# S32K324_M7 register map
Vendor: NXP Semiconductors; File version: 1.1
CPU: CM7 r0p1, little endian, MPU, FPU, VTOR, 4 interrupt priority bits
Registers are 32-bit, read-write, reset 0x0 unless marked. A register's access mark holds for its fields unless they carry their own. Offsets are from the block's base; [hi:lo] are bit positions; {n}, {i} and the like mark numbered series; 'fields as' and 'values as' point back to an identical list.

## EMAC (part 3 of 3)
Base 0x40480000
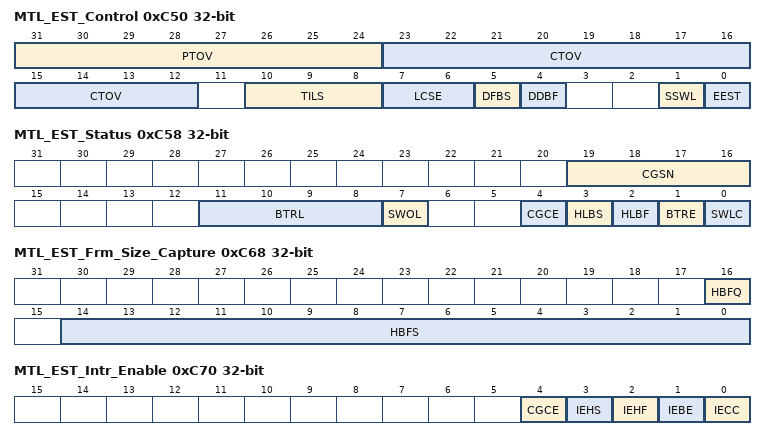
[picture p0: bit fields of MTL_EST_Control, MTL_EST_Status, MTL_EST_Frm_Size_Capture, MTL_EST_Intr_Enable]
0xC50 MTL_EST_Control
  [31:24] PTOV — PTP Time Offset Value
  [23:12] CTOV — Current Time Offset Value
  [10:8] TILS — Time Interval Left Shift Amount
  [7:6] LCSE — Loop Count to Report Scheduling Error
    0=M_4_ITERNS (4 iterations); 1=M_8_ITERNS (8 iterations); 2=M_16_ITERNS (16 iterations); 3=M_32_ITERNS (32 iterations)
  [5] DFBS — Drop Frames Causing Scheduling Error
    0=DONT_DROP (Do not drop frames); 1=DROP (Drop frames)
  [4] DDBF — Do not Drop Frames during Frame Size Error
    0=DROP (Drop frames during frame size error); 1=DONT_DROP (Do not Drop frames during frame size error)
  [1] SSWL — Switch to Software Owned List
    0=DISABLE (Disabled); 1=ENABLE (Enabled)
  [0] EEST — Enable EST
    0=DISABLE (Disabled); 1=ENABLE (Enabled)
0xC58 MTL_EST_Status
  [19:16] CGSN ro — Current GCL Slot Number Indicates the slot number of the GCL list
  [11:8] BTRL ro — BTR Error Loop Count Provides the minimum count (N) for which the equation Current Time =< New BTR + (N * New Cycle Time) becomes true
  [7] SWOL ro — S/W owned list When '0' indicates Gate control list number "0" is owned by software and when "1" indicates the Gate Control list "1" is owned by the software
    0=INACTIVE (Gate control list number "0" is owned by software); 1=ACTIVE (Gate control list number "1" is owned by software)
  [4] CGCE — Constant Gate Control Error This error occurs when the list length (LLR) is 1 and the Cycle Time (CTR) is less than or equal to the programmed Time Interval (TI) value after the optional Left Shifting
    0=INACTIVE (Constant Gate Control Error not detected); 1=ACTIVE (Constant Gate Control Error detected)
  [3] HLBS ro — Head-Of-Line Blocking due to Scheduling Set when the frame is not able to win arbitration and get scheduled even after 4 iterations of the GCL
    0=INACTIVE (Head-Of-Line Blocking due to Scheduling not detected); 1=ACTIVE (Head-Of-Line Blocking due to Scheduling detected)
  [2] HLBF ro — Head-Of-Line Blocking due to Frame Size Set when HOL Blocking is noticed on one or more Queues as a result of none of the Time Intervals of gate open in the GCL being greater than or equal to the duration needed for frame size (or frame fragment size when preemption is enabled) transmission
    0=INACTIVE (Head-Of-Line Blocking due to Frame Size not detected); 1=ACTIVE (Head-Of-Line Blocking due to Frame Size detected)
  [1] BTRE — BTR Error
    0=INACTIVE (BTR Error not detected); 1=ACTIVE (BTR Error detected)
  [0] SWLC — Switch to Software Owned List Complete
    0=INACTIVE (Not detected); 1=ACTIVE (Detected)
0xC60 MTL_EST_Sch_Error — MTL EST Scheduling Error
  [1:0] SEQN — Schedule Error Queue Number
0xC64 MTL_EST_Frm_Size_Error — MTL EST Frame Size Error
  [1:0] FEQN — Frame Size Error Queue Number
0xC68 MTL_EST_Frm_Size_Capture ro — MTL EST Frame Size Capture
  [16] HBFQ — Queue Number of HLBF
  [14:0] HBFS — Frame Size of HLBF
0xC70 MTL_EST_Intr_Enable — MTL EST Interrupt Enable
  [all] fields
    0=DISABLE (Disabled); 1=ENABLE (Enabled)
  [4] CGCE — Interrupt Enable for CGCE
  [3] IEHS — Interrupt Enable for HLBS
  [2] IEHF — Interrupt Enable for HLBF
  [1] IEBE — Interrupt Enable for BTR Error
  [0] IECC — Interrupt Enable for Switch List
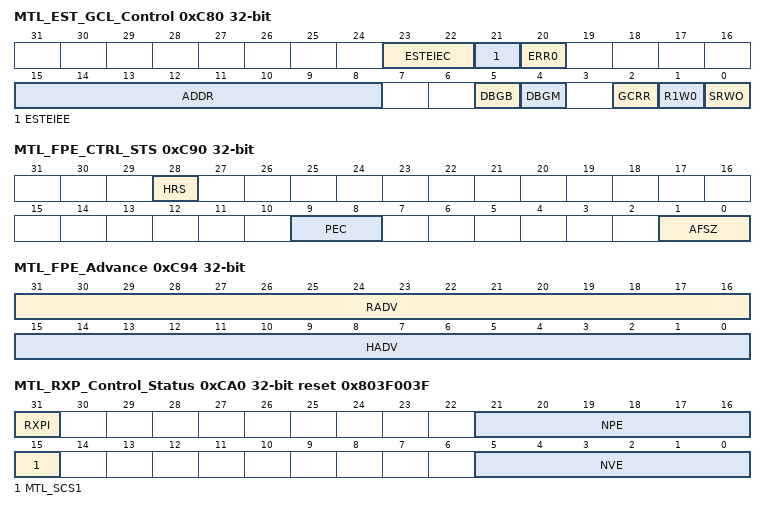
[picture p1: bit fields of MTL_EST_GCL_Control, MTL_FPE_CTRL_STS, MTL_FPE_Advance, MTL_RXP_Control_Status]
0xC80 MTL_EST_GCL_Control
  [23:22] ESTEIEC — ECC Inject Error Control for EST Memory
    0=M_1BIT (Insert 1 bit error); 1=M_2BIT (Insert 2 bit errors); 2=M_3BIT (Insert 3 bit errors); 3=M_1BIT_ADDR (Insert 1 bit error in address field)
  [21] ESTEIEE — EST ECC Inject Error Enable
    0=DISABLE (Disabled); 1=ENABLE (Enabled)
  [20] ERR0 — If this field is 1, it indicates that when the software writes to GCL the last write operation was aborted and when MTL_EST_Control[SSWL] is 1, GCL registers are prohibited
    0=DISABLE (ERR0 is disabled); 1=ENABLE (ERR1 is enabled)
  [15:8] ADDR — Gate Control List Address: (GCLA when GCRR is "0")
  [5] DBGB — Debug Mode Bank Select
    0=BANK0 (Directed to bank 0); 1=BANK1 (Directed to bank 1)
  [4] DBGM — Debug Mode
    0=DISABLE (Disabled); 1=ENABLE (Enabled)
  [2] GCRR — Gate Control Related Registers
    0=DISABLE (Disabled); 1=ENABLE (Enabled)
  [1] R1W0 — Read '1', Write '0'
    0=WRITE (Write operation); 1=READ (Read operation)
  [0] SRWO — Start Read/Write Operation
    0=DISABLE (Disabled); 1=ENABLE (Enabled)
0xC84 MTL_EST_GCL_Data
  [31:0] GCD — Gate Control Data
0xC90 MTL_FPE_CTRL_STS — MTL FPE Control Status
  [28] HRS ro — Hold/Release Status
    0=SET_REL (Release state); 1=SET_HOLD (Hold state)
  [9:8] PEC — Preemption Classification
  [1:0] AFSZ — Additional Fragment Size
0xC94 MTL_FPE_Advance
  [31:16] RADV — Release Advance
  [15:0] HADV — Hold Advance
0xCA0 MTL_RXP_Control_Status reset 0x803F003F — MTL Rx Parser Control Status
  [31] RXPI ro — RX Parser in Idle State
    0=INACTIVE (Not in Idle state); 1=ACTIVE (Idle state)
  [21:16] NPE — Number of parsable entries in the Instruction table
  [15] MTL_SCS1
  [5:0] NVE — Number Of Valid Entry Address Or Index In The Instruction Table
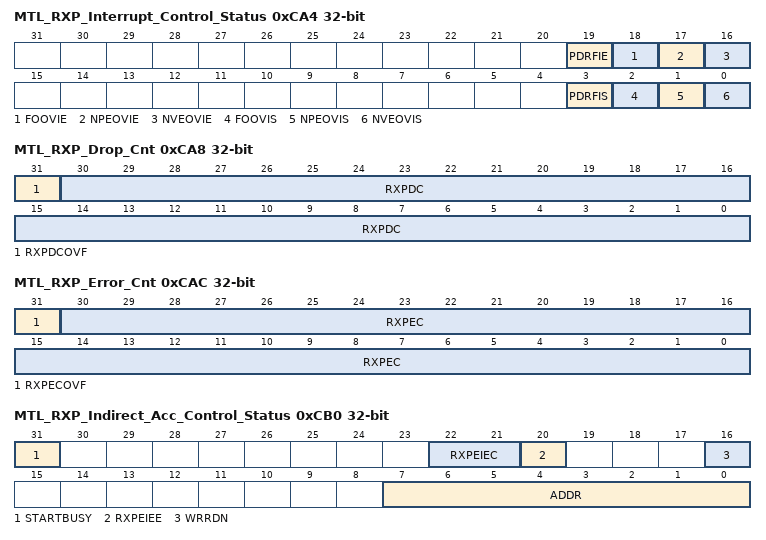
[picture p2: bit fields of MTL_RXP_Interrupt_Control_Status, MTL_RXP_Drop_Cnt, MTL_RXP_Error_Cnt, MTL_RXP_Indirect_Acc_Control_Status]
0xCA4 MTL_RXP_Interrupt_Control_Status — MTL Rx Parser Interrupt Control Status
  [19] PDRFIE — Packet Drop due to RF Interrupt Enable
    0=DISABLE (Disabled); 1=ENABLE (Enabled)
  [18] FOOVIE — Frame Offset Overflow Interrupt Enable
    0=DISABLE (Disabled); 1=ENABLE (Enabled)
  [17] NPEOVIE — Number of Parsable Entries Overflow Interrupt Enable
    0=DISABLE; 1=ENABLE
  [16] NVEOVIE — Number of Valid Entries Overflow Interrupt Enable
    0=DISABLE; 1=ENABLE
  [3] PDRFIS — Packet Dropped due to RF Interrupt Status
    0=INACTIVE (Not detected); 1=ACTIVE (Detected)
  [2] FOOVIS — Frame Offset Overflow Interrupt Status
    0=INACTIVE (Not detected); 1=ACTIVE (Detected)
  [1] NPEOVIS — Number of Parsable Entries Overflow Interrupt Status
    0=INACTIVE (Not detected); 1=ACTIVE (Detected)
  [0] NVEOVIS — Number of Valid Entry Address/Index Overflow Interrupt Status
    0=INACTIVE (Not detected); 1=ACTIVE (Detected)
0xCA8 MTL_RXP_Drop_Cnt ro — MTL Rx Parser Drop Count
  [31] RXPDCOVF — Rx Parser Drop Counter Overflow Bit
    0=INACTIVE (Not occurred); 1=ACTIVE (Occurred)
  [30:0] RXPDC — Rx Parser Drop Count
0xCAC MTL_RXP_Error_Cnt ro — MTL Rx Parser Error Count
  [31] RXPECOVF — Rx Parser Error Counter Overflow Bit
    0=INACTIVE (Not occurred); 1=ACTIVE (Occurred)
  [30:0] RXPEC — Rx Parser Error Count
0xCB0 MTL_RXP_Indirect_Acc_Control_Status — MTL Rx Parser Indirect Access Control Status
  [31] STARTBUSY — FRP Instruction Table Access Busy
    0=INACTIVE (hardware not busy); 1=ACTIVE (hardware is busy (Read/Write operation from/to the Rx Parser Memory))
  [22:21] RXPEIEC — ECC Inject Error Control for Rx Parser Memory
    values as MTL_EST_GCL_Control.ESTEIEC
  [20] RXPEIEE — ECC Inject Error Enable for Rx Parser Memory
    0=DISABLE (Disabled); 1=ENABLE (Enabled)
  [16] WRRDN — Read Write Control
    0=READ (Read operation to the receive parser memory); 1=WRITE (Write operation to the receive parser memory)
  [7:0] ADDR — FRP Instruction Table Offset Address
0xCB4 MTL_RXP_Indirect_Acc_Data ro — MTL Rx Parser Indirect Access Data
  [31:0] DATA — FRP Instruction Table Write/Read Data
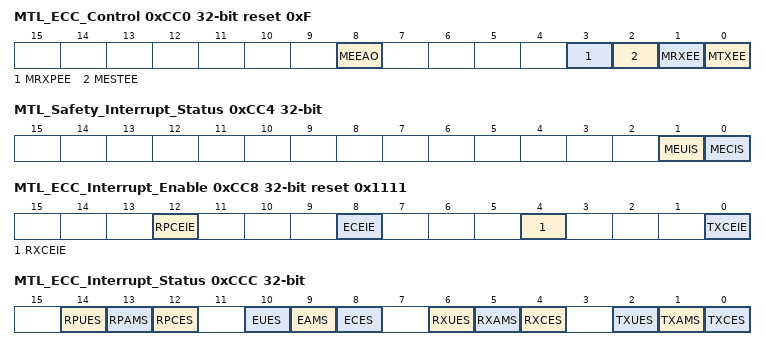
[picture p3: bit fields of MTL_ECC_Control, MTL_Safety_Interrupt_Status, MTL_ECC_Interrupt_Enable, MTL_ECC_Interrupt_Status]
0xCC0 MTL_ECC_Control reset 0xF
  [8] MEEAO — MTL ECC Error Address Status Over-ride
    0=DISABLE; 1=ENABLE
  [3] MRXPEE — MTL Rx Parser ECC Enable
    0=DISABLE (Disabled); 1=ENABLE (Enabled)
  [2] MESTEE — MTL EST ECC Enable
    0=DISABLE (Disabled); 1=ENABLE (Enabled)
  [1] MRXEE — MTL Rx FIFO ECC Enable
    0=DISABLE (Disabled); 1=ENABLE (Enabled)
  [0] MTXEE — MTL Tx FIFO ECC Enable
    0=DISABLE (Disabled); 1=ENABLE (Enabled)
0xCC4 MTL_Safety_Interrupt_Status ro — MTL Safety Interript Status
  [1] MEUIS — MTL ECC Uncorrectable Error Interrupt Status
    0=INACTIVE (Not detected); 1=ACTIVE (Detected)
  [0] MECIS — MTL ECC Correctable Error Interrupt Status
    0=INACTIVE (MTL ECC Correctable error Interrupt Status not detected); 1=ACTIVE (MTL ECC Correctable error Interrupt Status detected)
0xCC8 MTL_ECC_Interrupt_Enable reset 0x1111
  [all] fields
    0=DISABLE (Disabled); 1=ENABLE (Enabled)
  [12] RPCEIE — Rx Parser Memory Correctable Error Interrupt Enable
  [8] ECEIE — EST Memory Correctable Error Interrupt Enable
  [4] RXCEIE — Rx Memory Correctable Error Interrupt Enable
  [0] TXCEIE — Tx Memory Correctable Error Interrupt Enable
0xCCC MTL_ECC_Interrupt_Status
  [all] fields
    0=INACTIVE (Not detected); 1=ACTIVE (Detected)
  [14] RPUES — Rx Parser Memory Uncorrectable Error Status
  [13] RPAMS — MTL Rx Parser Memory Address Mismatch Status
  [12] RPCES — MTL Rx Parser Memory Correctable Error Status
  [10] EUES — MTL EST Memory Uncorrectable Error Status
  [9] EAMS — MTL EST Memory Address Mismatch Status
  [8] ECES — MTL EST Memory Correctable Error Status
  [6] RXUES — MTL Rx Memory Uncorrectable Error Status
  [5] RXAMS — MTL Rx Memory Address Mismatch Status
  [4] RXCES — MTL Rx memory Correctable Error Status
  [2] TXUES — MTL Tx Memory Uncorrectable Error Status
  [1] TXAMS — MTL Tx Memory Address Mismatch Status
  [0] TXCES — MTL Tx Memory Correctable Error Status
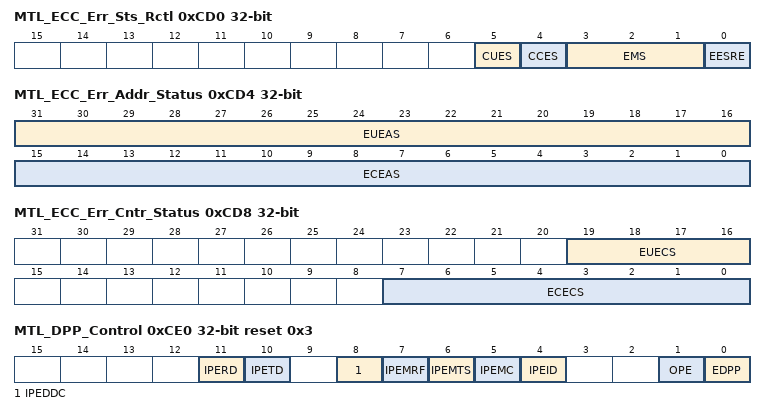
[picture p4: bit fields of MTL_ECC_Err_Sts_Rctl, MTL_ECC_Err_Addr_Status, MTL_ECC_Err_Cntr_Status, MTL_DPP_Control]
0xCD0 MTL_ECC_Err_Sts_Rctl — MTL ECC Error Status
  [5] CUES — Clear Uncorrectable Error Status
    0=INACTIVE (Not detected); 1=ACTIVE (Detected)
  [4] CCES — Clear Correctable Error Status
    0=INACTIVE (Not detected); 1=ACTIVE (Detected)
  [3:1] EMS — MTL ECC Memory Selection
    0=TX_MEM (MTL Tx memory); 1=RX_MEM (MTL Rx memory); 2=EST_MEM (MTL EST memory); 3=RXP_MEM (MTL Rx Parser memory); 4=TSO_MEM (DMA TSO memory)
  [0] EESRE — MTL ECC Error Status Read Enable
    0=DISABLE (Disabled); 1=ENABLE (Enabled)
0xCD4 MTL_ECC_Err_Addr_Status ro — MTL ECC Error Adress Status
  [31:16] EUEAS — MTL ECC Uncorrectable Error Address Status
  [15:0] ECEAS — MTL ECC Correctable Error Address Status
0xCD8 MTL_ECC_Err_Cntr_Status ro — MTL ECC Error Control Status
  [19:16] EUECS — MTL ECC Uncorrectable Error Counter Status Based on the EMS field of MTL_ECC_Err_Cntr_Rctl register, this field holds the respective memory's uncorrectable error count value
  [7:0] ECECS — MTL ECC Correctable Error Counter Status Based on the EMS field of MTL_ECC_Err_Cntr_Rctl register, this field holds the respective memory's correctable error count value
0xCE0 MTL_DPP_Control reset 0x3
  [11] IPERD — Insert Parity error in Rx write-back Descriptor parity generator
    0=DISABLE (Disabled); 1=ENABLE (Enabled)
  [10] IPETD — Insert Parity error in Tx write-back Descriptor parity generator
    0=DISABLE (Disabled); 1=ENABLE (Enabled)
  [8] IPEDDC — Insert Parity Error in DMA DTX Control Word Parity Generator
    0=DISABLE (Disabled); 1=ENABLE (Enabled)
  [7] IPEMRF — Insert Parity Error in MTL Rx FIFO Read Control Parity Generator
    0=DISABLE (Disabled); 1=ENABLE (Enabled)
  [6] IPEMTS — Insert Parity Error in MTL Tx Status Parity Generator
    0=DISABLE (Disabled); 1=ENABLE (Enabled)
  [5] IPEMC — Insert Parity Error in MTL Checksum Parity Generator
    0=DISABLE (Disabled); 1=ENABLE (Enabled)
  [4] IPEID — Insert Parity Error in Interface Data Parity Generator
    0=DISABLE (Disabled); 1=ENABLE (Enabled)
  [1] OPE ro — Odd Parity Enable
    0=DISABLE (Disabled); 1=ENABLE (Enabled)
  [0] EDPP — Enable Data path Parity Protection
    0=DISABLE; 1=ENABLE
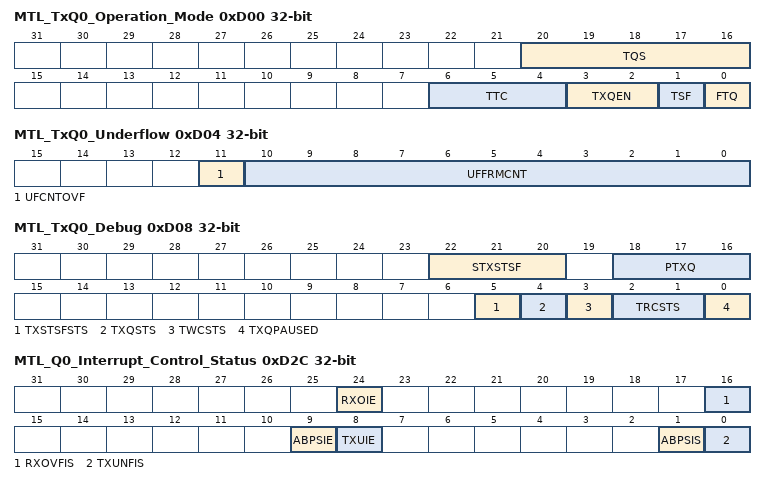
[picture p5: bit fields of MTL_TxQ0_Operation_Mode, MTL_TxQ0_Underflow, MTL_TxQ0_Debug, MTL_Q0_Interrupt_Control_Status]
0xD00 MTL_TxQ0_Operation_Mode — MTL Tx Queue 0 Operation Mode
  [20:16] TQS — Transmit Queue Size
  [6:4] TTC — Transmit Threshold Control
    0=M_32BYTES (32); 1=M_64BYTES (64); 2=M_96BYTES (96); 3=M_128BYTES (128); 4=M_192BYTES (192); 5=M_256BYTES (256); 6=M_384BYTES (384); 7=M_512BYTES (512)
  [3:2] TXQEN — Transmit Queue Enable
    0=DISABLE (Not enabled); 1=EN_IF_AV (Enable in AV mode (Reserved in non-AV)); 2=ENABLE (Enabled)
  [1] TSF — Transmit Store and Forward
    0=DISABLE (Disabled); 1=ENABLE (Enabled)
  [0] FTQ — Flush Transmit Queue
    0=DISABLE (Disabled); 1=ENABLE (Enabled)
0xD04 MTL_TxQ0_Underflow ro — MTL Tx Queue 0 Underflow
  [11] UFCNTOVF — Overflow Bit for Underflow Packet Counter
    0=INACTIVE (Not detected); 1=ACTIVE (Detected)
  [10:0] UFFRMCNT — Underflow Packet Counter
0xD08 MTL_TxQ0_Debug ro — MTL Tx Queue 0 Debug
  [22:20] STXSTSF — Number of Status Words in Tx Status FIFO of Queue
  [18:16] PTXQ — Number of Packets in the Transmit Queue
  [5] TXSTSFSTS — MTL Tx Status FIFO Full Status
    0=INACTIVE (Not detected); 1=ACTIVE (Detected)
  [4] TXQSTS — MTL Tx Queue Not Empty Status
    0=INACTIVE (Not detected); 1=ACTIVE (Detected)
  [3] TWCSTS — MTL Tx Queue Write Controller Status
    0=INACTIVE (Not detected); 1=ACTIVE (Detected)
  [2:1] TRCSTS — MTL Tx Queue Read Controller Status
    0=IDLE (Idle state); 1=READ (Read state (transferring data to the MAC transmitter)); 2=WAIT (Waiting for pending transit status from the MAC transmitter); 3=FLUSH (Flushing the transit queue because of the packet abort request from the MAC)
  [0] TXQPAUSED — Transmit Queue in Pause
    0=INACTIVE (Not detected); 1=ACTIVE (Detected)
0xD14 MTL_TxQ0_ETS_Status ro — MTL Tx Queue 0 ETS Status
  [23:0] ABS — Average Bits per Slot
0xD18 MTL_TxQ0_Quantum_Weight — MTL Tx Queue Quantum Weight
  [20:0] ISCQW — Quantum or Weights
0xD2C MTL_Q0_Interrupt_Control_Status — MTL Queue 0 Interrupt Control Status
  [24] RXOIE — Receive Queue Overflow Interrupt Enable
    0=DISABLE (Disabled); 1=ENABLE (Enabled)
  [16] RXOVFIS — Receive Queue Overflow Interrupt Status
    0=INACTIVE (Not detected); 1=ACTIVE (Detected)
  [9] ABPSIE — Average Bits Per Slot Interrupt Enable
    0=DISABLE (Disabled); 1=ENABLE (Enabled)
  [8] TXUIE — Transmit Queue Underflow Interrupt Enable
    0=DISABLE (Disabled); 1=ENABLE (Enabled)
  [1] ABPSIS — Average Bits Per Slot Interrupt Status
    0=INACTIVE (Not detected); 1=ACTIVE (Detected)
  [0] TXUNFIS — Transmit Queue Underflow Interrupt Status
    0=INACTIVE (Not detected); 1=ACTIVE (Detected)
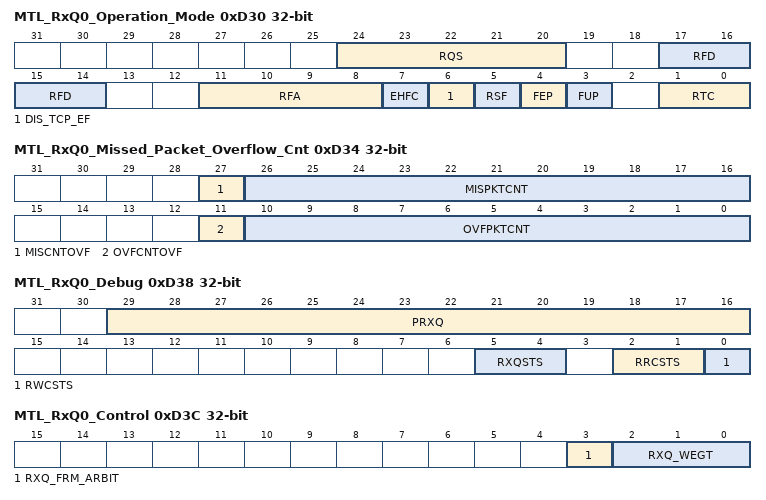
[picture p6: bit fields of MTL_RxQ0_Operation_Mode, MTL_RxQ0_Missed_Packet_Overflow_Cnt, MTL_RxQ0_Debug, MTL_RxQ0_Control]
0xD30 MTL_RxQ0_Operation_Mode — MTL Rx Queue 0 Operation Mode
  [24:20] RQS — Receive Queue Size
  [17:14] RFD — Threshold for Deactivating Flow Control (in half-duplex and full-duplex modes)
  [11:8] RFA — Threshold for Activating Flow Control (in half-duplex and full-duplex)
  [7] EHFC — Enable Hardware Flow Control
    0=DISABLE; 1=ENABLE
  [6] DIS_TCP_EF — Disable Dropping of TCP/IP Checksum Error Packets
    0=ENABLE; 1=DISABLE
  [5] RSF — Receive Queue Store and Forward
    0=DISABLE (Disabled); 1=ENABLE (Enabled)
  [4] FEP — Forward Error Packets
    0=DISABLE (Disabled); 1=ENABLE (Enabled)
  [3] FUP — Forward Undersized Good Packets
    0=DISABLE (Disabled); 1=ENABLE (Enabled)
  [1:0] RTC — Receive Queue Threshold Control
    0=M_64BYTE (64); 1=M_32BYTE (32); 2=M_96BYTE (96); 3=M_128BYTE (128)
0xD34 MTL_RxQ0_Missed_Packet_Overflow_Cnt ro — MTL Rx Queue Missed Packet Overflow Count
  [27] MISCNTOVF — Missed Packet Counter Overflow Bit
    0=INACTIVE (Not detected); 1=ACTIVE (Detected)
  [26:16] MISPKTCNT — Missed Packet Counter
  [11] OVFCNTOVF — Overflow Counter Overflow Bit
    0=INACTIVE (Not detected); 1=ACTIVE (Detected)
  [10:0] OVFPKTCNT — Overflow Packet Counter
0xD38 MTL_RxQ0_Debug ro — MTL Rx Queue 0 Debug
  [29:16] PRXQ — Number of Packets in Receive Queue
  [5:4] RXQSTS — MTL Rx Queue Fill-Level Status
    0=EMPTY (Rx Queue empty); 1=BLW_THR (Rx Queue fill-level below flow-control deactivate threshold); 2=ABV_THR (Rx Queue fill-level above flow-control activate threshold); 3=FULL (Rx Queue full)
  [2:1] RRCSTS — MTL Rx Queue Read Controller State
    0=IDLE (Idle state); 1=READ_DATA (Reading packet data); 2=READ_STS (Reading packet status (or timestamp)); 3=FLUSH (Flushing the packet data and status)
  [0] RWCSTS — MTL Rx Queue Write Controller Active Status
    0=INACTIVE (Not detected); 1=ACTIVE (Detected)
0xD3C MTL_RxQ0_Control — MTL Rx Queue 0 Control 0
  [3] RXQ_FRM_ARBIT — Receive Queue Packet Arbitration
    0=DISABLE (Disabled); 1=ENABLE (Enabled)
  [2:0] RXQ_WEGT — Receive Queue Weight
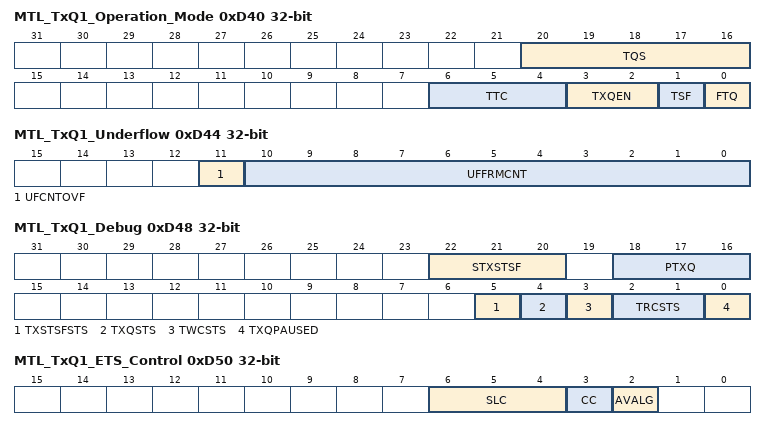
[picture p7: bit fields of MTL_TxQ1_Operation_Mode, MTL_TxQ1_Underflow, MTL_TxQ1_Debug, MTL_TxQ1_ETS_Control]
0xD40 MTL_TxQ1_Operation_Mode — MTL Tx Queue 1 Operation Mode
  [20:16] TQS — Transmit Queue Size
  [6:4] TTC — Transmit Threshold Control
    values as MTL_TxQ0_Operation_Mode.TTC
  [3:2] TXQEN — Transmit Queue Enable
    values as MTL_TxQ0_Operation_Mode.TXQEN
  [1] TSF — Transmit Store and Forward
    0=DISABLE (Transmit Store and Forward is disabled); 1=ENABLE (Transmit Store and Forward is enabled)
  [0] FTQ — Flush Transmit Queue
    0=DISABLE (Disabled); 1=ENABLE (Enabled)
0xD44 MTL_TxQ1_Underflow ro — MTL Tx Queue 1 Underflow
  fields as MTL_TxQ0_Underflow
0xD48 MTL_TxQ1_Debug ro — MTL Tx Queue 1 Debug
  fields as MTL_TxQ0_Debug
0xD50 MTL_TxQ1_ETS_Control — MTL Tx Queue 1 ETS Control
  [6:4] SLC — Slot Count
    0=M_1_SLOT (1 slot); 1=M_2_SLOT (2 slots); 2=M_4_SLOT (4 slots); 3=M_8_SLOT (8 slots); 4=M_16_SLOT (16 slots)
  [3] CC — Credit Control
    0=DISABLE (Disabled); 1=ENABLE (Enabled)
  [2] AVALG — AV Algorithm
    0=DISABLE (Disabled); 1=ENABLE (Enabled)
0xD54 MTL_TxQ1_ETS_Status ro — MTL Tx Queue 1 ETS Status
  [23:0] ABS — Average Bits per Slot
0xD58 MTL_TxQ1_Quantum_Weight — MTL Tx Queue 1 Quantum Weight
  [20:0] ISCQW — idleSlopeCredit, Quantum or Weights
0xD5C MTL_TxQ1_SendSlopeCredit — MTL Tx Queue 1 Sendslope Credit
  [13:0] SSC — sendSlopeCredit Value
0xD60 MTL_TxQ1_HiCredit — MTL Tx Queue 1 HiCredit
  [28:0] HC — hiCredit Value
0xD64 MTL_TxQ1_LoCredit — MTL Tx Queue 1 LoCredit
  [28:0] LC — loCredit Value
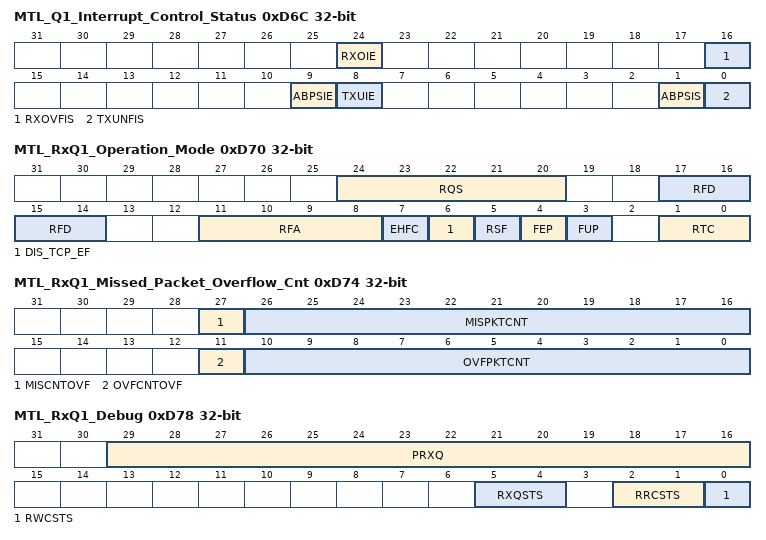
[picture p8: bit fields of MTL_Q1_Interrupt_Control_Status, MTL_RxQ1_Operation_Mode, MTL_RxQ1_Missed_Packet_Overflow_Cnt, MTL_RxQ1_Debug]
0xD6C MTL_Q1_Interrupt_Control_Status — MTL Queue 1 Interrupt Control Status
  [24] RXOIE — Receive Queue Overflow Interrupt Enable
    0=DISABLE; 1=ENABLE
  [16] RXOVFIS — Receive Queue Overflow Interrupt Status
    0=INACTIVE (Not detected); 1=ACTIVE (Detected)
  [9] ABPSIE — Average Bits Per Slot Interrupt Enable
    0=DISABLE (Disabled); 1=ENABLE (Enabled)
  [8] TXUIE — Transmit Queue Underflow Interrupt Enable
    0=DISABLE (Disabled); 1=ENABLE (Enabled)
  [1] ABPSIS — Average Bits Per Slot Interrupt Status
    0=INACTIVE (Not detected); 1=ACTIVE (Detected)
  [0] TXUNFIS — Transmit Queue Underflow Interrupt Status
    0=INACTIVE (Not detected); 1=ACTIVE (Detected)
0xD70 MTL_RxQ1_Operation_Mode — MTL Rx Queue 1 Operation Mode
  [24:20] RQS — Receive Queue Size
  [17:14] RFD — Threshold for Deactivating Flow Control (in half-duplex and full-duplex modes)
  [11:8] RFA — Threshold for Activating Flow Control (in half-duplex and full-duplex
  [7] EHFC — Enable Hardware Flow Control
    0=DISABLE; 1=ENABLE
  [6] DIS_TCP_EF — Disable Dropping of TCP or IP Checksum Error Packets
    0=ENABLE (Enabled); 1=DISABLE (Disabled)
  [5] RSF — Receive Queue Store and Forward
    0=DISABLE (Disabled); 1=ENABLE (Enabled)
  [4] FEP — Forward Error Packets
    0=DISABLE (Disabled); 1=ENABLE (Enabled)
  [3] FUP — Forward Undersized Good Packets
    0=DISABLE (Disabled); 1=ENABLE (Enabled)
  [1:0] RTC — Receive Queue Threshold Control
    values as MTL_RxQ0_Operation_Mode.RTC
0xD74 MTL_RxQ1_Missed_Packet_Overflow_Cnt ro — MTL Rx Queue 1 Missed Packet Overflow Counter
  fields as MTL_RxQ0_Missed_Packet_Overflow_Cnt
0xD78 MTL_RxQ1_Debug ro — MTL Rx Queue 1 Debug
  fields as MTL_RxQ0_Debug
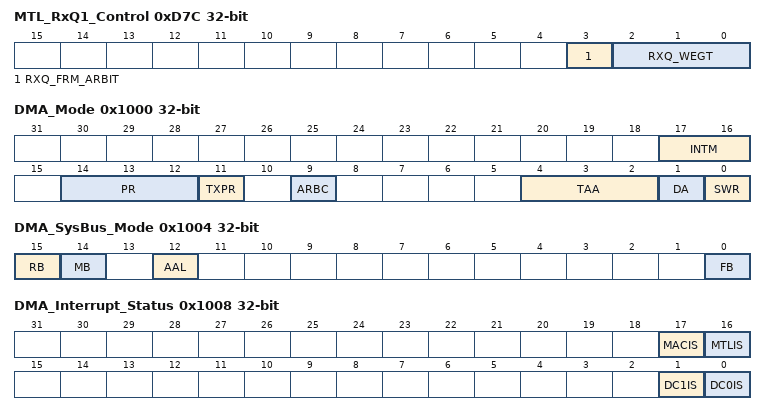
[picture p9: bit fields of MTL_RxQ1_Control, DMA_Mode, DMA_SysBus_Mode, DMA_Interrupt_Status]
0xD7C MTL_RxQ1_Control — MTL Rx Queue 1 Control
  fields as MTL_RxQ0_Control
0x1000 DMA_Mode
  [17:16] INTM — Interrupt Mode
    0=MODE0 (See above description); 1=MODE1 (See above description); 2=MODE2 (See above description)
  [14:12] PR — Priority Ratio
    {v}=R_{v+1}_1 (The priority ratio is {v+1}:1) (v=0..7)
  [11] TXPR — Transmit Priority
    0=DISABLE (Disabled); 1=ENABLE (Enabled)
  [9] ARBC — Is reserved for NXP internal use
    0=DISABLE (NXP reserved field disabled); 1=ENABLE (NXP reserved field enabled up on NXP request)
  [4:2] TAA — Transmit Arbitration Algorithm
    0=FP (Fixed priority (Channel 0 has the lowest priority and the last channel has the highest priority)); 1=WSP (Weighted Strict Priority (WSP)); 2=WRR (Weighted Round-Robin (WRR))
  [1] DA — DMA Tx or Rx Arbitration Scheme
    0=WRR (Weighted Round-Robin with Rx:Tx or Tx:Rx); 1=FP (Fixed Priority)
  [0] SWR — Software Reset
    0=DISABLE (Disabled); 1=ENABLE (Enabled)
0x1004 DMA_SysBus_Mode — DMA System Bus Mode
  [all] fields
    0=DISABLE (Disabled); 1=ENABLE (Enabled)
  [15] RB — Rebuild INCRx Burst
  [14] MB — Mixed Burst
  [12] AAL — Address-Aligned Beats
  [0] FB — Fixed Burst Length
0x1008 DMA_Interrupt_Status ro
  [all] fields
    0=INACTIVE (Not detected); 1=ACTIVE (Detected)
  [17] MACIS — MAC Interrupt Status
  [16] MTLIS — MTL Interrupt Status
  [1] DC1IS — DMA Channel 1 Interrupt Status
  [0] DC0IS — DMA Channel 0 Interrupt Status
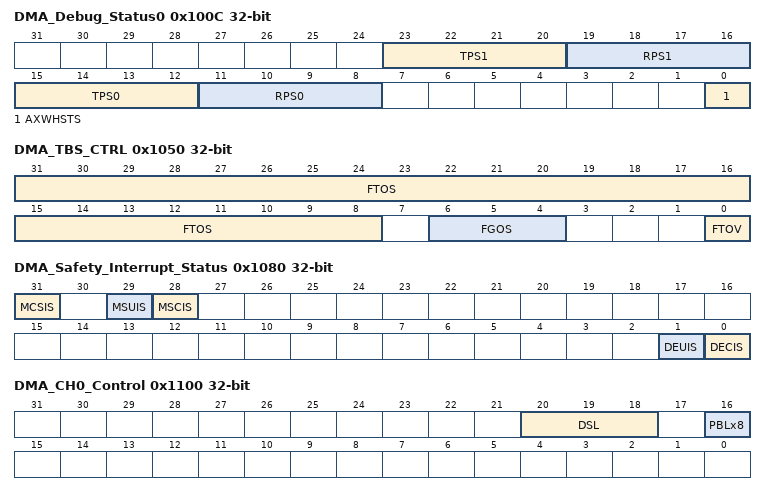
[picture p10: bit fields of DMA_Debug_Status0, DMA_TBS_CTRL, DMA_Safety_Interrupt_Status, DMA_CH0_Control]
0x100C DMA_Debug_Status0 ro
  [23:20] TPS1 — DMA Channel 1 Transmit Process State
    0=STOP (Stopped (Reset or stop transmit command issued)); 1=RUN_FTTD (Running (Fetching transmit transfer descriptor)); 2=RUN_WS (Running (Waiting for status)); 3=RUN_RDS (Running (Reading data from system memory buffer and queuing it to the transmit buffer (Tx FIFO))); 4=TSTMP_WS (Timestamp write state); 6=SUSPND (Suspended (Transmit descriptor unavailable or transmit buffer underflow)); 7=RUN_CTD (Running (Closing transmit descriptor))
  [19:16] RPS1 — DMA Channel 1 Receive Process State
    0=STOP (Stopped (Reset or Stop receive command issued)); 1=RUN_FRTD (Running (Fetching receive transfer descriptor)); 3=RUN_WRP (Running (Waiting for receive packet)); 4=SUSPND (Suspended (Receive descriptor unavailable)); 5=RUN_CRD (Running (Closing the receive descriptor)); 6=TSTMP (Timestamp write state); 7=RUN_TRP (Running (Transferring the received packet data from the receive buffer to the system memory))
  [15:12] TPS0 — DMA Channel 0 Transmit Process State
    values as TPS1
  [11:8] RPS0 — DMA Channel 0 Receive Process State
    0=STOP (Stopped (Reset or stop receive command issued)); 1=RUN_FRTD (Running (Fetching receive transfer descriptor)); 3=RUN_WRP (Running (Waiting for receive packet)); 4=SUSPND (Suspended (Receive descriptor unavailable)); 5=RUN_CRD (Running (Closing the receive descriptor)); 6=TSTMP (Timestamp write state); 7=RUN_TRP (Running (Transferring the received packet data from the receive buffer to the system memory))
  [0] AXWHSTS — AHB Master Status
    0=INACTIVE (Not detected); 1=ACTIVE (detected)
0x1050 DMA_TBS_CTRL — DMA TBS Control
  [31:8] FTOS — Fetch Time Offset
  [6:4] FGOS — Fetch GSN Offset
  [0] FTOV — Fetch Time Offset Valid
    0=INVALID; 1=VALID
0x1080 DMA_Safety_Interrupt_Status ro
  [all] fields
    0=INACTIVE (Not detected); 1=ACTIVE (Detected)
  [31] MCSIS — MAC Safety Uncorrectable Interrupt Status
  [29] MSUIS — MTL Safety Uncorrectable Error Interrupt Status
  [28] MSCIS — MTL Safety Correctable Error Interrupt Status
  [1] DEUIS — DMA ECC Uncorrectable Error Interrupt Status
  [0] DECIS — DMA ECC Correctable Error Interrupt Status
0x1100 DMA_CH0_Control — DMA Channel 0 Control
  [20:18] DSL — Descriptor Skip Length
  [16] PBLx8 — 8xPBL mode
    0=DISABLE (Disabled); 1=ENABLE (Enabled)
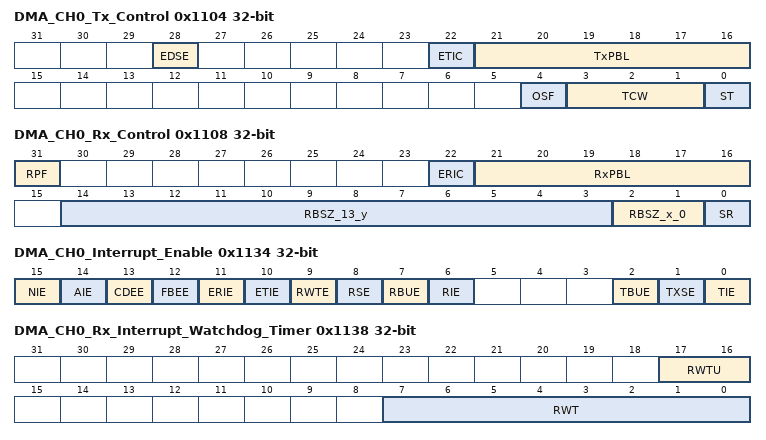
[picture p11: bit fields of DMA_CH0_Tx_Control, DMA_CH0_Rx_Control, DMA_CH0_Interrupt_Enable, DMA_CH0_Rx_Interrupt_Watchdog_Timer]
0x1104 DMA_CH0_Tx_Control — DMA Channel Tx Control
  [28] EDSE — Enhanced Descriptor Enable
    0=DISABLE (Disabled); 1=ENABLE (Enabled)
  [22] ETIC — Early Transmit Interrupt Control
    0=DISABLE (Disabled); 1=ENABLE (Enabled)
  [21:16] TxPBL — Transmit Programmable Burst Length
  [4] OSF — Operate on Second Packet
    0=DISABLE (Disabled); 1=ENABLE (Enabled)
  [3:1] TCW — Transmit Channel Weight
  [0] ST — Start or Stop Transmission Command
    0=STOP; 1=START
0x1108 DMA_CH0_Rx_Control — DMA Channel Rx Control
  [31] RPF — Rx Packet Flush
    0=DISABLE (Disabled); 1=ENABLE (Enabled)
  [22] ERIC — Early Receive Interrupt Control
    0=DISABLE (Disabled); 1=ENABLE (Enabled)
  [21:16] RxPBL — Receive Programmable Burst Length
  [14:3] RBSZ_13_y — Receive Buffer size High
  [2:1] RBSZ_x_0 ro — Receive Buffer size Low
  [0] SR — Start or Stop Receive
    0=STOP; 1=START
0x1114 DMA_CH0_TxDesc_List_Address — DMA Channel 0 Tx Descriptor List Address
  [31:2] TDESLA — Start of Transmit List
0x111C DMA_CH0_RxDesc_List_Address — DMA Channel 0 Rx Descriptor List Address
  [31:2] RDESLA — Start of Receive List
0x1120 DMA_CH0_TxDesc_Tail_Pointer — DMA Channel 0 Tx Descriptor Tail Pointer
  [31:2] TDTP — Transmit Descriptor Tail Pointer
0x1128 DMA_CH0_RxDesc_Tail_Pointer — DMA Channeli 0 Rx Descriptor List Pointer
  [31:2] RDTP — Receive Descriptor Tail Pointer
0x112C DMA_CH0_TxDesc_Ring_Length — DMA Channel 0 Tx Descriptor Ring Length
  [9:0] TDRL — Transmit Descriptor Ring Length
0x1130 DMA_CH0_RxDesc_Ring_Length — DMA Channel 0 Rx Descriptor Ring Length
  [9:0] RDRL — Receive Descriptor Ring Length
0x1134 DMA_CH0_Interrupt_Enable — DMA Channel 0 Interrupt Enable
  [all] fields
    0=DISABLE; 1=ENABLE
  [15] NIE — Normal Interrupt Summary Enable
  [14] AIE — Abnormal Interrupt Summary Enable
  [13] CDEE — Context Descriptor Error Enable
  [12] FBEE — Fatal Bus Error Enable
  [11] ERIE — Early Receive Interrupt Enable
  [10] ETIE — Early Transmit Interrupt Enable
  [9] RWTE — Receive Watchdog Timeout Enable
  [8] RSE — Receive Stopped Enable
  [7] RBUE — Receive Buffer Unavailable Enable
  [6] RIE — Receive Interrupt Enable
  [2] TBUE — Transmit Buffer Unavailable Enable
  [1] TXSE — Transmit Stopped Enable
  [0] TIE — Transmit Interrupt Enable
0x1138 DMA_CH0_Rx_Interrupt_Watchdog_Timer — DMA Channel 0 Rx Interrupt Watchdog Timer
  [17:16] RWTU — Receive Interrupt Watchdog Timer Count Units
  [7:0] RWT — Receive Interrupt Watchdog Timer Count
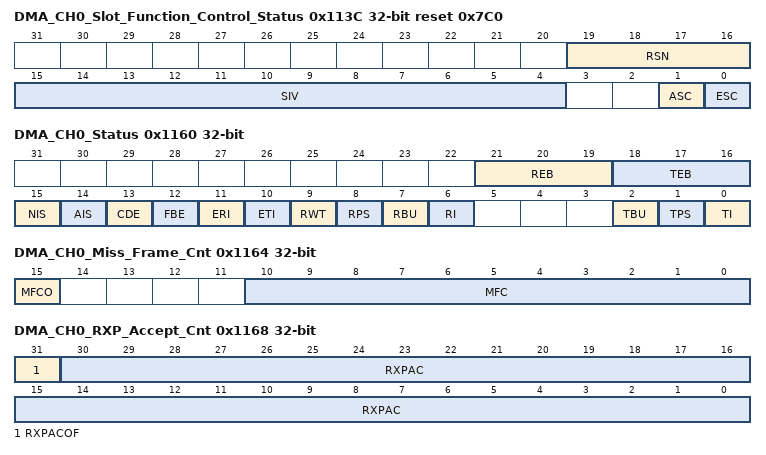
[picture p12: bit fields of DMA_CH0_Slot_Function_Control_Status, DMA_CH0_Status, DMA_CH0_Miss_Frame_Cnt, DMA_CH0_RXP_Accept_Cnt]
0x113C DMA_CH0_Slot_Function_Control_Status reset 0x7C0 — DMA Channel 0 Slot Function Control Status
  [19:16] RSN ro — Reference Slot Number
  [15:4] SIV — Slot Interval Value
  [1] ASC — Advance Slot Check
    0=DISABLE (Disabled); 1=ENABLE (Enabled)
  [0] ESC — Enable Slot Comparison
    0=DISABLE (Disabled); 1=ENABLE (Enabled)
0x1144 DMA_CH0_Current_App_TxDesc ro — DMA Channel 0 Current Application Transmit Descriptor
  [31:0] CURTDESAPTR — Application Transmit Descriptor Address Pointer
0x114C DMA_CH0_Current_App_RxDesc ro — DMA Channel 0 Current Application Receive Descriptor
  [31:0] CURRDESAPTR — Application Receive Descriptor Address Pointer
0x1154 DMA_CH0_Current_App_TxBuffer ro — DMA Channel 0 Current Application Transmit Descriptor
  [31:0] CURTBUFAPTR — Application Transmit Buffer Address Pointer
0x115C DMA_CH0_Current_App_RxBuffer ro — DMA Channel 0 Current Application Receive Buffer
  [31:0] CURRBUFAPTR — Application Receive Buffer Address Pointer
0x1160 DMA_CH0_Status — DMA Channel 0 Status
  [21:19] REB ro — Rx DMA Error Bits
  [18:16] TEB ro — Tx DMA Error Bits
  [15] NIS — Normal Interrupt Summary
    0=INACTIVE (Not detected); 1=ACTIVE (Detected)
  [14] AIS — Abnormal Interrupt Summary
    0=INACTIVE (Not detected); 1=ACTIVE (Detected)
  [13] CDE — Context Descriptor Error
    0=INACTIVE (Not detected); 1=ACTIVE (Detected)
  [12] FBE — Fatal Bus Error
    0=INACTIVE (Not detected); 1=ACTIVE (Detected)
  [11] ERI — Early Receive Interrupt
    0=INACTIVE (Not detected); 1=ACTIVE (Detected)
  [10] ETI — Early Transmit Interrupt
    0=INACTIVE (Not detected); 1=ACTIVE (Detected)
  [9] RWT — Receive Watchdog Timeout
    0=INACTIVE (Not detected); 1=ACTIVE (Detected)
  [8] RPS — Receive Process Stopped
    0=INACTIVE (Not detected); 1=ACTIVE (Detected)
  [7] RBU — Receive Buffer Unavailable
    0=INACTIVE (Not detected); 1=ACTIVE (Detected)
  [6] RI — Receive Interrupt
    0=INACTIVE (Not detected); 1=ACTIVE (Detected)
  [2] TBU — Transmit Buffer Unavailable
    0=INACTIVE (Not detected); 1=ACTIVE (Detected)
  [1] TPS — Transmit Process Stopped
    0=INACTIVE (Not detected); 1=ACTIVE (Detected)
  [0] TI — Transmit Interrupt
    0=INACTIVE (Not detected); 1=ACTIVE (Detected)
0x1164 DMA_CH0_Miss_Frame_Cnt ro — DMA Channel 0 Miss Frame Counter
  [15] MFCO — Overflow status of the MFC Counter
    0=INACTIVE (Not occurred); 1=ACTIVE (Occurred)
  [10:0] MFC — Dropped Packet Counters Indicates the number of packet counters that DMA drops either because of bus error or because of programing RPF field in DMA_CH${i}_Rx_Control register
0x1168 DMA_CH0_RXP_Accept_Cnt ro — DMA Channel 0 Rx Parser Accept Count
  [31] RXPACOF — Rx Parser Accept Counter Overflow Bit
    0=INACTIVE (Not occurred); 1=ACTIVE (Occurred)
  [30:0] RXPAC — Rx Parser Accept Counter
0x116C DMA_CH0_RX_ERI_Cnt ro — DMA Channel 0 Rx ERI Count
  [11:0] ECNT — ERI Counter
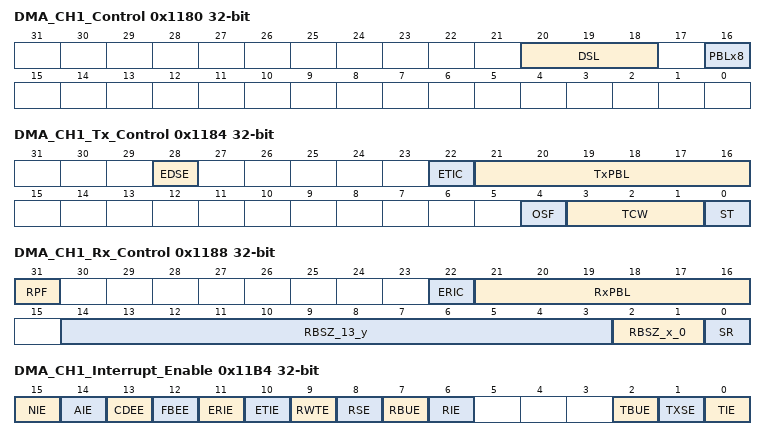
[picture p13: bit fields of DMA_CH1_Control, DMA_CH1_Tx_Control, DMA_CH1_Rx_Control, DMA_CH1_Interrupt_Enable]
0x1180 DMA_CH1_Control — DMA Channel 1 Control
  fields as DMA_CH0_Control
0x1184 DMA_CH1_Tx_Control — DMA Channel 1 Tx Control
  fields as DMA_CH0_Tx_Control
0x1188 DMA_CH1_Rx_Control — DMA Channel 1 Rx Control
  fields as DMA_CH0_Rx_Control
0x1194 DMA_CH1_TxDesc_List_Address — DMA Channel 1 Tx Descriptor List Address
  [31:2] TDESLA — Start of Transmit List
0x119C DMA_CH1_RxDesc_List_Address — DMA Channel 1 Rx Descriptor List Address
  [31:2] RDESLA — Start of Receive List
0x11A0 DMA_CH1_TxDesc_Tail_Pointer — DMA Channel 1 Tx Descriptor Tail Pointer
  [31:2] TDTP — Transmit Descriptor Tail Pointer
0x11A8 DMA_CH1_RxDesc_Tail_Pointer — DMA Channel 1 Rx Descriptor Tail Pointer
  [31:2] RDTP — Receive Descriptor Tail Pointer
0x11AC DMA_CH1_TxDesc_Ring_Length — DMA Channel 1 Tx Descriptor Ring Length
  [9:0] TDRL — Transmit Descriptor Ring Length
0x11B0 DMA_CH1_RxDesc_Ring_Length — DMA Channel 1 Rx Descriptor Ring Length
  [9:0] RDRL — Receive Descriptor Ring Length
0x11B4 DMA_CH1_Interrupt_Enable — DMA Channel 1 Interrupt Enable
  fields as DMA_CH0_Interrupt_Enable
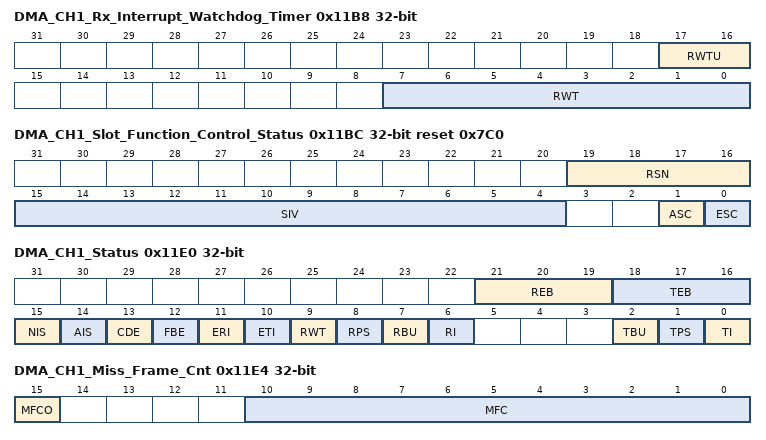
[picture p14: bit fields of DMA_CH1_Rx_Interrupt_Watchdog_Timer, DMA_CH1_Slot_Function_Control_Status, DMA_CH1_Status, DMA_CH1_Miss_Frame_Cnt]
0x11B8 DMA_CH1_Rx_Interrupt_Watchdog_Timer — DMA Channel 1 Rx Interrupt Watchdog Timer
  fields as DMA_CH0_Rx_Interrupt_Watchdog_Timer
0x11BC DMA_CH1_Slot_Function_Control_Status reset 0x7C0 — DMA Channel 1 Slot Function Control Status
  [19:16] RSN ro — Reference Slot Number
  [15:4] SIV — Slot Interval Value
  [1] ASC — Advance Slot Check
    0=DISABLE (Disabled); 1=ENABLE (Enabled)
  [0] ESC — Enable Slot Comparison
    0=DISABLE; 1=ENABLE
0x11C4 DMA_CH1_Current_App_TxDesc ro — DMA Channel 1 Current Application Transmit Descriptor
  [31:0] CURTDESAPTR — Application Transmit Descriptor Address Pointer
0x11CC DMA_CH1_Current_App_RxDesc ro — DMA Channel 1 Current Application Receive Descriptor
  [31:0] CURRDESAPTR — Application Receive Descriptor Address Pointer
0x11D4 DMA_CH1_Current_App_TxBuffer ro — DMA Channel 1 Current Application Transmit Buffer
  [31:0] CURTBUFAPTR — Application Transmit Buffer Address Pointer
0x11DC DMA_CH1_Current_App_RxBuffer ro — DMA Channel 1 Current Application Receive Buffer
  [31:0] CURRBUFAPTR — Application Receive Buffer Address Pointer
0x11E0 DMA_CH1_Status — DMA Channel 1 Status
  fields as DMA_CH0_Status
0x11E4 DMA_CH1_Miss_Frame_Cnt ro — DMA Channel 1 Miss Frame Counter
  [15] MFCO — Overflow status of the MFC Counter
    0=INACTIVE (Not occurred); 1=ACTIVE (Occurred)
  [10:0] MFC — Dropped Packet Counters
0x11E8 DMA_CH1_RXP_Accept_Cnt ro — DMA Channel 1 Rx Parser Accept Count
  fields as DMA_CH0_RXP_Accept_Cnt
0x11EC DMA_CH1_RX_ERI_Cnt ro — DMA Channel 1 Rx ERI Count
  [11:0] ECNT — ERI Counter
